# STM32F7x3_v1r0 register map
File version: 1.0
Registers are 32-bit, read-write, reset 0x0 unless marked. A register's access mark holds for its fields unless they carry their own. Offsets are from the block's base; [hi:lo] are bit positions; {n}, {i} and the like mark numbered series.

## LPTIM1 — Low power timer
Base 0x40002400
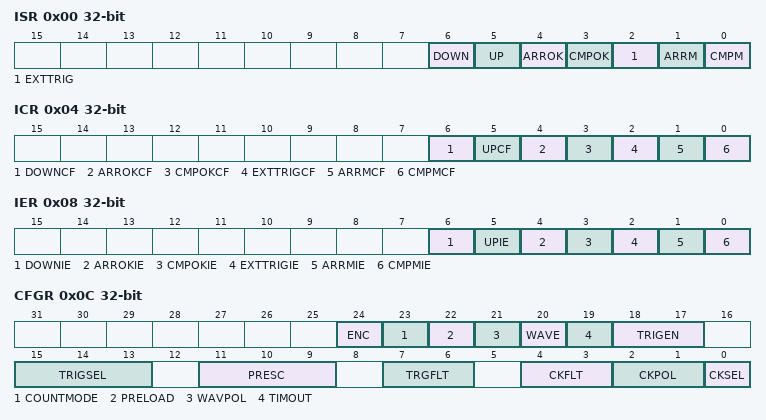
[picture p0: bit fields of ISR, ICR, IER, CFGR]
0x00 ISR ro — Interrupt and Status Register
  [6] DOWN — Counter direction change up to down
  [5] UP — Counter direction change down to up
  [4] ARROK — Autoreload register update OK
  [3] CMPOK — Compare register update OK
  [2] EXTTRIG — External trigger edge event
  [1] ARRM — Autoreload match
  [0] CMPM — Compare match
0x04 ICR wo — Interrupt Clear Register
  [6] DOWNCF — Direction change to down Clear Flag
  [5] UPCF — Direction change to UP Clear Flag
  [4] ARROKCF — Autoreload register update OK Clear Flag
  [3] CMPOKCF — Compare register update OK Clear Flag
  [2] EXTTRIGCF — External trigger valid edge Clear Flag
  [1] ARRMCF — Autoreload match Clear Flag
  [0] CMPMCF — compare match Clear Flag
0x08 IER — Interrupt Enable Register
  [6] DOWNIE — Direction change to down Interrupt Enable
  [5] UPIE — Direction change to UP Interrupt Enable
  [4] ARROKIE — Autoreload register update OK Interrupt Enable
  [3] CMPOKIE — Compare register update OK Interrupt Enable
  [2] EXTTRIGIE — External trigger valid edge Interrupt Enable
  [1] ARRMIE — Autoreload match Interrupt Enable
  [0] CMPMIE — Compare match Interrupt Enable
0x0C CFGR — Configuration Register
  [24] ENC — Encoder mode enable
  [23] COUNTMODE — counter mode enabled
  [22] PRELOAD — Registers update mode
  [21] WAVPOL — Waveform shape polarity
  [20] WAVE — Waveform shape
  [19] TIMOUT — Timeout enable
  [18:17] TRIGEN — Trigger enable and polarity
  [15:13] TRIGSEL — Trigger selector
  [11:9] PRESC — Clock prescaler
  [7:6] TRGFLT — Configurable digital filter for trigger
  [4:3] CKFLT — Configurable digital filter for external clock
  [2:1] CKPOL — Clock Polarity
  [0] CKSEL — Clock selector
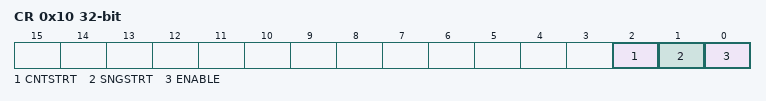
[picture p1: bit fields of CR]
0x10 CR — Control Register
  [2] CNTSTRT — Timer start in continuous mode
  [1] SNGSTRT — LPTIM start in single mode
  [0] ENABLE — LPTIM Enable
0x14 CMP — Compare Register
  [15:0] CMP — Compare value
0x18 ARR reset 0x1 — Autoreload Register
  [15:0] ARR — Auto reload value
0x1C CNT ro — Counter Register
  [15:0] CNT — Counter value

## NVIC — Nested Vectored Interrupt Controller
Base 0xE000E000
0x04 ICTR ro — Interrupt Controller Type Register
  [3:0] INTLINESNUM — Total number of interrupt lines in groups
{0x100+4i} ISER{i} (i=0..2) — Interrupt Set-Enable Register
  [31:0] SETENA
{0x180+4i} ICER{i} (i=0..2) — Interrupt Clear-Enable Register
  [31:0] CLRENA
{0x200+4i} ISPR{i} (i=0..2) — Interrupt Set-Pending Register
  [31:0] SETPEND
{0x280+4i} ICPR{i} (i=0..2) — Interrupt Clear-Pending Register
  [31:0] CLRPEND
{0x300+4i} IABR{i} ro (i=0..2) — Interrupt Active Bit Register
  [31:0] ACTIVE
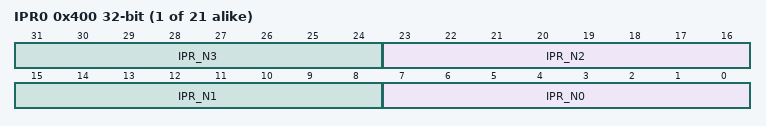
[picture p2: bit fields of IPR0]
{0x400+4i} IPR{i} (i=0..20) — Interrupt Priority Register
  [8n+7:8n] IPR_N{n} (n=0..3)
0xF00 STIR wo — Software Triggered Interrupt Register
  [8:0] INTID — interrupt to be triggered

## PWR — Power control
Base 0x40007000
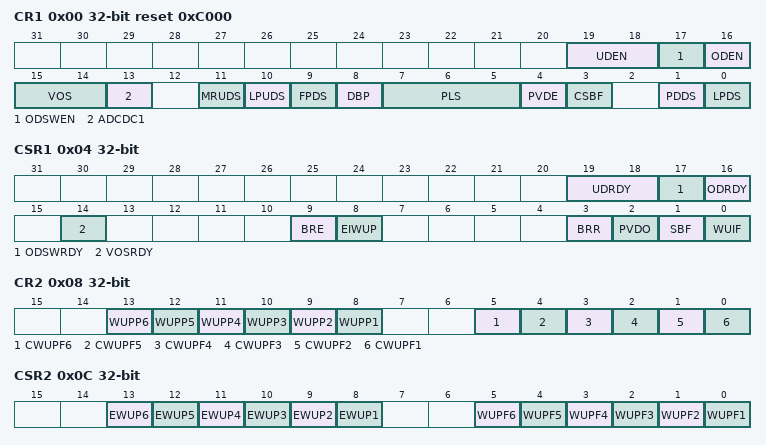
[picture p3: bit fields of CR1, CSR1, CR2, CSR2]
0x00 CR1 reset 0xC000 — power control register
  [19:18] UDEN — Under-drive enable in stop mode
  [17] ODSWEN — Over-drive switching enabled
  [16] ODEN — Over-drive enable
  [15:14] VOS — Regulator voltage scaling output selection
  [13] ADCDC1
  [11] MRUDS — Main regulator in deepsleep under-drive mode
  [10] LPUDS — Low-power regulator in deepsleep under-drive mode
  [9] FPDS — Flash power down in Stop mode
  [8] DBP — Disable backup domain write protection
  [7:5] PLS — PVD level selection
  [4] PVDE — Power voltage detector enable
  [3] CSBF — Clear standby flag
  [1] PDDS — Power down deepsleep
  [0] LPDS — Low-power deep sleep
0x04 CSR1 access per field — power control/status register
  [19:18] UDRDY rw — Under-drive ready flag
  [17] ODSWRDY rw — Over-drive mode switching ready
  [16] ODRDY rw — Over-drive mode ready
  [14] VOSRDY rw — Regulator voltage scaling output selection ready bit
  [9] BRE rw — Backup regulator enable
  [8] EIWUP rw — Enable internal wakeup
  [3] BRR ro — Backup regulator ready
  [2] PVDO ro — PVD output
  [1] SBF ro — Standby flag
  [0] WUIF ro — Wakeup internal flag
0x08 CR2 access per field — power control register
  [13] WUPP6 rw — Wakeup pin polarity bit for PI11
  [12] WUPP5 rw — Wakeup pin polarity bit for PI8
  [11] WUPP4 rw — Wakeup pin polarity bit for PC13
  [10] WUPP3 rw — Wakeup pin polarity bit for PC1
  [9] WUPP2 rw — Wakeup pin polarity bit for PA2
  [8] WUPP1 rw — Wakeup pin polarity bit for PA0
  [5] CWUPF6 ro — Clear Wakeup Pin flag for PI11
  [4] CWUPF5 ro — Clear Wakeup Pin flag for PI8
  [3] CWUPF4 ro — Clear Wakeup Pin flag for PC13
  [2] CWUPF3 ro — Clear Wakeup Pin flag for PC1
  [1] CWUPF2 ro — Clear Wakeup Pin flag for PA2
  [0] CWUPF1 ro — Clear Wakeup Pin flag for PA0
0x0C CSR2 access per field — power control/status register
  [13] EWUP6 rw — Enable Wakeup pin for PI11
  [12] EWUP5 rw — Enable Wakeup pin for PI8
  [11] EWUP4 rw — Enable Wakeup pin for PC13
  [10] EWUP3 rw — Enable Wakeup pin for PC1
  [9] EWUP2 rw — Enable Wakeup pin for PA2
  [8] EWUP1 rw — Enable Wakeup pin for PA0
  [5] WUPF6 ro — Wakeup Pin flag for PI11
  [4] WUPF5 ro — Wakeup Pin flag for PI8
  [3] WUPF4 ro — Wakeup Pin flag for PC13
  [2] WUPF3 ro — Wakeup Pin flag for PC1
  [1] WUPF2 ro — Wakeup Pin flag for PA2
  [0] WUPF1 ro — Wakeup Pin flag for PA0
